# CM_CORE__IVA register map
Vendor: Texas Instruments
Peripheral module from a debugger description file (folder TDA2Px).
Registers are 32-bit, access per field, reset 0x3 unless marked. A register's access mark holds for its fields unless they carry their own. Offsets are as the file gives them; lines under a group give offsets from that group; [hi:lo] are bit positions; {n}, {i} and the like mark numbered series; 'fields as' and 'values as' point back to an identical list; <NAME> marks a mode.

## CM_CORE__IVA
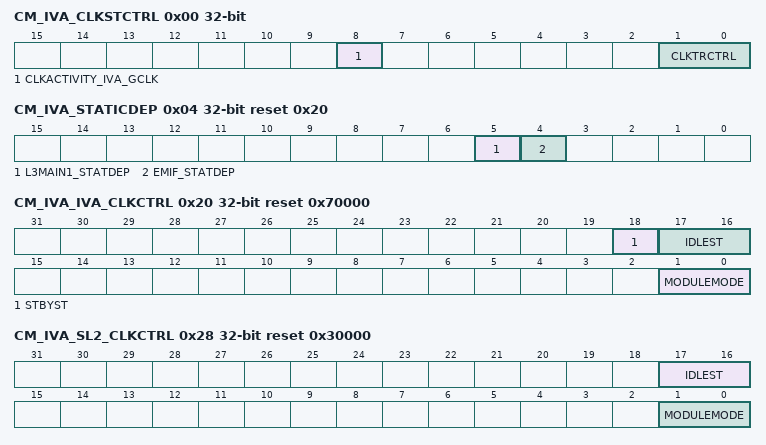
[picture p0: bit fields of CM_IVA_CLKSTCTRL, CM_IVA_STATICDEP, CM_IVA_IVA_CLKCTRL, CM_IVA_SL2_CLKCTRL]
0x00 CM_IVA_CLKSTCTRL — This register enables the IVA domain power state transition. It controls the HW supervised domain power state transition between ON-ACTIVE and ON-INACTIVE states. It also hold one status bit per clock input of the domain.
  [8] CLKACTIVITY_IVA_GCLK ro — This field indicates the state of the IVA_ROOT_CLK clock input of the domain. [warm reset insensitive]
    0=INACT (Corresponding clock is definitely gated); 1=ACT (Corresponding clock is running or gating/ungating transition is on-going)
  [1:0] CLKTRCTRL rw — Controls the clock state transition of the IVA clock domain.
    0=NO_SLEEP (NO_SLEEP: Sleep transition cannot be initiated. Wakeup transition may however occur.); 1=SW_SLEEP (SW_SLEEP: Start a software forced sleep transition on the domain.); 2=SW_WKUP (SW_WKUP: Start a software forced wake-up transition on the domain.); 3=HW_AUTO (HW_AUTO: Automatic transition is enabled. Sleep and wakeup transition are based upon hardware conditions.)
0x04 CM_IVA_STATICDEP reset 0x20 — This register controls the static domain depedencies from IVA domain towards 'target' domains. It is relevant only for domain having system initiator(s).
  [5] L3MAIN1_STATDEP ro — Static dependency towards L3MAIN1 clock domain
    1=ENABLED (Dependency is enabled)
  [4] EMIF_STATDEP rw — Static dependency towards EMIF clock domain
    0=DISABLED (Dependency is disabled); 1=ENABLED (Dependency is enabled)
0x08 CM_IVA_DYNAMICDEP ro reset 0x0 — This register controls the dynamic domain depedencies from IVA domain towards 'target' domains. It is relevant only for domain having OCP master port(s).
  [5] L3MAIN1_DYNDEP — Dynamic dependency towards L3MAIN1 clock domain
    0=DISABLED (Dependency is disabled)
0x20 CM_IVA_IVA_CLKCTRL reset 0x70000 — This register manages the IVA clocks.
  [18] STBYST ro — Module standby status. [warm reset insensitive]
    0=FUNC (Module is functional (not in standby)); 1=STANDBY (Module is in standby)
  [17:16] IDLEST ro — Module idle status. [warm reset insensitive]
    0=FUNC (Module is fully functional, including OCP); 1=TRANS (Module is performing transition: wakeup, or sleep, or sleep abortion); 2=IDLE (Module is in Idle mode (only OCP part). It is functional if using separate functional clock); 3=DISABLE (Module is disabled and cannot be accessed)
  [1:0] MODULEMODE rw — Control the way mandatory clocks are managed.
    0=DISABLED (Module is disabled by SW. Any OCP access to module results in an error, except if resulting from a module wakeup (asynchronous wakeup).); 1=AUTO (Module is managed automatically by HW according to clock domain transition. A clock domain sleep transition put module into idle. A wakeup domain transition put it back into function. If CLKTRCTRL=3, any OCP access to module is always granted. Module clocks may be gated according to the clock domain state.)
0x28 CM_IVA_SL2_CLKCTRL reset 0x30000 — This register manages the SL2 clocks.
  [17:16] IDLEST ro — Module idle status. [warm reset insensitive]
    values as CM_IVA_IVA_CLKCTRL.IDLEST
  [1:0] MODULEMODE rw — Control the way mandatory clocks are managed.
    values as CM_IVA_IVA_CLKCTRL.MODULEMODE
